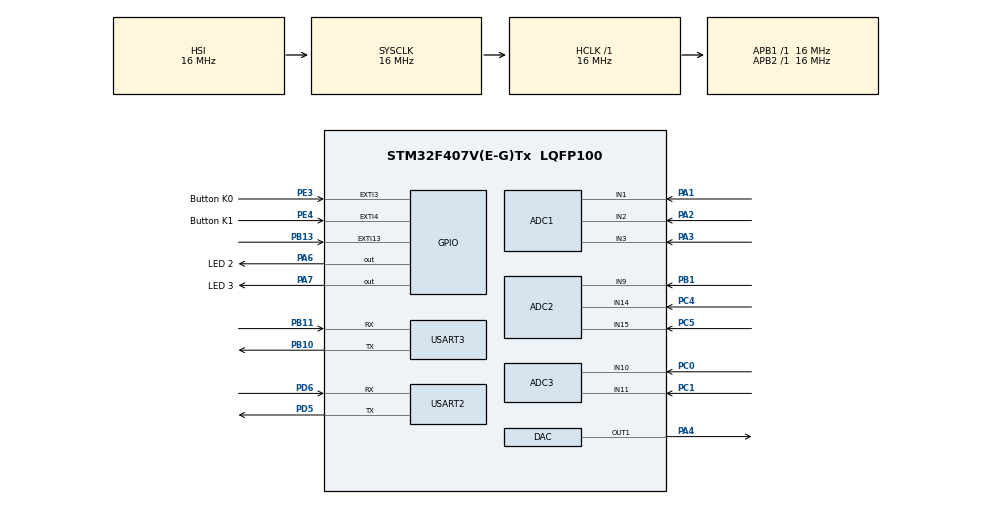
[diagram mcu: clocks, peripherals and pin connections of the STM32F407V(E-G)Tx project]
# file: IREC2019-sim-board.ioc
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ADC1.Channel-1\#ChannelRegularConversion=ADC_CHANNEL_3
ADC1.NbrOfConversionFlag=1
ADC1.Rank-1\#ChannelRegularConversion=1
ADC1.SamplingTime-1\#ChannelRegularConversion=ADC_SAMPLETIME_3CYCLES
ADC1.master=1
ADC2.Channel-0\#ChannelRegularConversion=ADC_CHANNEL_9
ADC2.NbrOfConversionFlag=1
ADC2.Rank-0\#ChannelRegularConversion=1
ADC2.SamplingTime-0\#ChannelRegularConversion=ADC_SAMPLETIME_3CYCLES
ADC3.Channel-1\#ChannelRegularConversion=ADC_CHANNEL_10
ADC3.NbrOfConversionFlag=1
ADC3.Rank-1\#ChannelRegularConversion=1
ADC3.SamplingTime-1\#ChannelRegularConversion=ADC_SAMPLETIME_3CYCLES
Mcu.Family=STM32F4
Mcu.Name=STM32F407V(E-G)Tx
Mcu.Package=LQFP100
NVIC.EXTI15_10_IRQn=true\:0\:0\:false\:false\:true\:true\:true
NVIC.PriorityGroup=NVIC_PRIORITYGROUP_4
NVIC.USART2_IRQn=true\:0\:0\:false\:false\:true\:true\:true
NVIC.USART3_IRQn=true\:0\:0\:false\:false\:true\:true\:true
PA1.Signal=ADCx_IN1
PA13.Mode=Serial_Wire
PA13.Signal=SYS_JTMS-SWDIO
PA14.Mode=Serial_Wire
PA14.Signal=SYS_JTCK-SWCLK
PA2.Signal=ADCx_IN2
PA3.Signal=ADCx_IN3
PA4.Signal=COMP_DAC1_group
PA6.GPIO_Label=LED 2
PA6.Signal=GPIO_Output
PA7.GPIO_Label=LED 3
PA7.Signal=GPIO_Output
PB1.Signal=ADCx_IN9
PB10.Mode=Asynchronous
PB10.Signal=USART3_TX
PB11.Mode=Asynchronous
PB11.Signal=USART3_RX
PB13.GPIO_ModeDefaultEXTI=GPIO_MODE_IT_FALLING
PB13.Signal=GPXTI13
PC0.Signal=ADCx_IN10
PC1.Signal=ADCx_IN11
PC14-OSC32_IN.Mode=LSE-External-Oscillator
PC14-OSC32_IN.Signal=RCC_OSC32_IN
PC15-OSC32_OUT.Mode=LSE-External-Oscillator
PC15-OSC32_OUT.Signal=RCC_OSC32_OUT
PC4.Signal=ADCx_IN14
PC5.Signal=ADCx_IN15
PD5.Mode=Asynchronous
PD5.Signal=USART2_TX
PD6.Mode=Asynchronous
PD6.Signal=USART2_RX
PE3.GPIO_Label=Button K0
PE3.Signal=GPXTI3
PE4.GPIO_Label=Button K1
PE4.Signal=GPXTI4
PH0-OSC_IN.Mode=HSE-External-Oscillator
PH0-OSC_IN.Signal=RCC_OSC_IN
PH1-OSC_OUT.Mode=HSE-External-Oscillator
PH1-OSC_OUT.Signal=RCC_OSC_OUT
ProjectManager.HeapSize=0x200
ProjectManager.StackSize=0x400
ProjectManager.TargetToolchain=SW4STM32
RCC.AHBFreq_Value=16000000
RCC.APB1Freq_Value=16000000
RCC.APB2Freq_Value=16000000
RCC.CortexFreq_Value=16000000
RCC.HSE_VALUE=25000000
RCC.HSI_VALUE=16000000
RCC.SYSCLKFreq_VALUE=16000000
RCC.VCOOutputFreq_Value=192000000
SH.ADCx_IN1.0=ADC1_IN1,IN1
SH.ADCx_IN10.0=ADC3_IN10,IN10
SH.ADCx_IN11.0=ADC3_IN11,IN11
SH.ADCx_IN14.0=ADC2_IN14,IN14
SH.ADCx_IN15.0=ADC2_IN15,IN15
SH.ADCx_IN2.0=ADC1_IN2,IN2
SH.ADCx_IN3.0=ADC1_IN3,IN3
SH.ADCx_IN9.0=ADC2_IN9,IN9
SH.COMP_DAC1_group.0=DAC_OUT1,DAC_OUT1
USART2.VirtualMode=VM_ASYNC
USART3.VirtualMode=VM_ASYNC
board=custom

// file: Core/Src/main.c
/* USER CODE BEGIN Header */
/**
  ******************************************************************************
  * @file           : main.c
  * @brief          : Main program body
  ******************************************************************************
  * @attention
  *
  * <h2><center>&copy; Copyright (c) 2019 STMicroelectronics.
  * All rights reserved.</center></h2>
  *
  * This software component is licensed by ST under BSD 3-Clause license,
  * the "License"; You may not use this file except in compliance with the
  * License. You may obtain a copy of the License at:
  *                        opensource.org/licenses/BSD-3-Clause
  *
  ******************************************************************************
  */
/* USER CODE END Header */

#include "main.h"
#include "adc.h"
#include "dac.h"
#include "usart.h"
#include "gpio.h"

/* USER CODE BEGIN Includes */
#include <FlightComputer.h>
/* USER CODE END Includes */

void SystemClock_Config(void);

int main(void)
{

  /* MCU Configuration--------------------------------------------------------*/

  /* Reset of all peripherals, Initializes the Flash interface and the Systick. */
  HAL_Init();

  /* Configure the system clock */
  SystemClock_Config();

  /* Initialize all configured peripherals */
  MX_GPIO_Init();
  MX_ADC1_Init();
  MX_ADC2_Init();
  MX_ADC3_Init();
  MX_DAC_Init();
  MX_USART2_UART_Init();
  MX_USART3_UART_Init();
  /* USER CODE BEGIN 2 */
  FC_Setup();
  /* USER CODE END 2 */

  /* Infinite loop */
  while (1)
  {

    /* USER CODE BEGIN 3 */
    FC_Tick();
  }
  /* USER CODE END 3 */
}

void SystemClock_Config(void)
{
  RCC_OscInitTypeDef RCC_OscInitStruct = {0};
  RCC_ClkInitTypeDef RCC_ClkInitStruct = {0};

  /** Configure the main internal regulator output voltage
  */
  __HAL_RCC_PWR_CLK_ENABLE();
  __HAL_PWR_VOLTAGESCALING_CONFIG(PWR_REGULATOR_VOLTAGE_SCALE1);
  /** Initializes the CPU, AHB and APB busses clocks
  */
  RCC_OscInitStruct.OscillatorType = RCC_OSCILLATORTYPE_HSI;
  RCC_OscInitStruct.HSIState = RCC_HSI_ON;
  RCC_OscInitStruct.HSICalibrationValue = RCC_HSICALIBRATION_DEFAULT;
  RCC_OscInitStruct.PLL.PLLState = RCC_PLL_NONE;
  if (HAL_RCC_OscConfig(&RCC_OscInitStruct) != HAL_OK)
  {
    Error_Handler();
  }
  /** Initializes the CPU, AHB and APB busses clocks
  */
  RCC_ClkInitStruct.ClockType = RCC_CLOCKTYPE_HCLK|RCC_CLOCKTYPE_SYSCLK
                              |RCC_CLOCKTYPE_PCLK1|RCC_CLOCKTYPE_PCLK2;
  RCC_ClkInitStruct.SYSCLKSource = RCC_SYSCLKSOURCE_HSI;
  RCC_ClkInitStruct.AHBCLKDivider = RCC_SYSCLK_DIV1;
  RCC_ClkInitStruct.APB1CLKDivider = RCC_HCLK_DIV1;
  RCC_ClkInitStruct.APB2CLKDivider = RCC_HCLK_DIV1;

  if (HAL_RCC_ClockConfig(&RCC_ClkInitStruct, FLASH_LATENCY_0) != HAL_OK)
  {
    Error_Handler();
  }
}

void Error_Handler(void)
{
}

/************************ (C) COPYRIGHT STMicroelectronics *****END OF FILE****/
